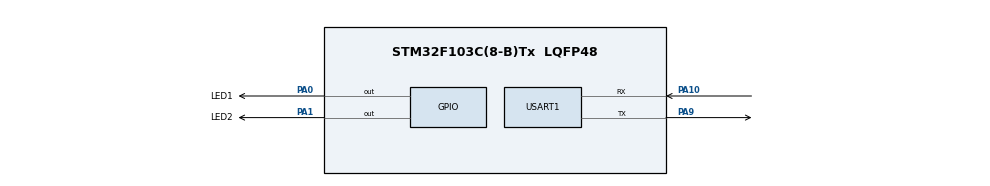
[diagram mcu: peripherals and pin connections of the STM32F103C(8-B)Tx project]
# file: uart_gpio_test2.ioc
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Mcu.Family=STM32F1
Mcu.Name=STM32F103C(8-B)Tx
Mcu.Package=LQFP48
NVIC.PriorityGroup=NVIC_PRIORITYGROUP_4
NVIC.USART1_IRQn=true\:0\:0\:false\:false\:true\:true\:true\:true
PA0-WKUP.GPIO_Label=LED1
PA0-WKUP.Signal=GPIO_Output
PA1.GPIO_Label=LED2
PA1.Signal=GPIO_Output
PA10.Mode=Asynchronous
PA10.Signal=USART1_RX
PA13.Mode=Serial_Wire
PA13.Signal=SYS_JTMS-SWDIO
PA14.Mode=Serial_Wire
PA14.Signal=SYS_JTCK-SWCLK
PA9.Mode=Asynchronous
PA9.Signal=USART1_TX
ProjectManager.HeapSize=0x200
ProjectManager.StackSize=0x400
ProjectManager.TargetToolchain=STM32CubeIDE
RCC.APB1Freq_Value=8000000
RCC.APB2Freq_Value=8000000
USART1.VirtualMode=VM_ASYNC
board=custom

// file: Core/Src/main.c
/* USER CODE BEGIN Header */
/**
  ******************************************************************************
  * @file           : main.c
  * @brief          : Main program body
  ******************************************************************************
  * @attention
  *
  * Copyright (c) 2026 STMicroelectronics.
  * All rights reserved.
  *
  * This software is licensed under terms that can be found in the LICENSE file
  * in the root directory of this software component.
  * If no LICENSE file comes with this software, it is provided AS-IS.
  *
  ******************************************************************************
  */
/* USER CODE END Header */
#include "main.h"

UART_HandleTypeDef huart1;

/* USER CODE BEGIN PV */
uint8_t rx_buf[2];  // UART'tan gelen 2 karakteri saklayan tampon (buffer)
/* USER CODE END PV */

void SystemClock_Config(void);
static void MX_GPIO_Init(void);
static void MX_USART1_UART_Init(void);

int main(void)
{

  /* MCU Configuration--------------------------------------------------------*/

  /* Reset of all peripherals, Initializes the Flash interface and the Systick. */
  HAL_Init();

  /* Configure the system clock */
  SystemClock_Config();

  /* Initialize all configured peripherals */
  MX_GPIO_Init();
  MX_USART1_UART_Init();
  /* USER CODE BEGIN 2 */
  HAL_UART_Receive_IT(&huart1, rx_buf, 2);  // UART'ı kesme modunda dinlemeye başlat: 2 karakter gelince kesme tetiklenir
  /* USER CODE END 2 */

  /* Infinite loop */
  while (1)
  {

  }
}

void SystemClock_Config(void)
{
  RCC_OscInitTypeDef RCC_OscInitStruct = {0};
  RCC_ClkInitTypeDef RCC_ClkInitStruct = {0};

  /** Initializes the RCC Oscillators according to the specified parameters
  * in the RCC_OscInitTypeDef structure.
  */
  RCC_OscInitStruct.OscillatorType = RCC_OSCILLATORTYPE_HSI;
  RCC_OscInitStruct.HSIState = RCC_HSI_ON;
  RCC_OscInitStruct.HSICalibrationValue = RCC_HSICALIBRATION_DEFAULT;
  RCC_OscInitStruct.PLL.PLLState = RCC_PLL_NONE;
  if (HAL_RCC_OscConfig(&RCC_OscInitStruct) != HAL_OK)
  {
    Error_Handler();
  }

  /** Initializes the CPU, AHB and APB buses clocks
  */
  RCC_ClkInitStruct.ClockType = RCC_CLOCKTYPE_HCLK|RCC_CLOCKTYPE_SYSCLK
                              |RCC_CLOCKTYPE_PCLK1|RCC_CLOCKTYPE_PCLK2;
  RCC_ClkInitStruct.SYSCLKSource = RCC_SYSCLKSOURCE_HSI;
  RCC_ClkInitStruct.AHBCLKDivider = RCC_SYSCLK_DIV1;
  RCC_ClkInitStruct.APB1CLKDivider = RCC_HCLK_DIV1;
  RCC_ClkInitStruct.APB2CLKDivider = RCC_HCLK_DIV1;

  if (HAL_RCC_ClockConfig(&RCC_ClkInitStruct, FLASH_LATENCY_0) != HAL_OK)
  {
    Error_Handler();
  }
}

static void MX_USART1_UART_Init(void)
{

  huart1.Instance = USART1;
  huart1.Init.BaudRate = 115200;
  huart1.Init.WordLength = UART_WORDLENGTH_8B;
  huart1.Init.StopBits = UART_STOPBITS_1;
  huart1.Init.Parity = UART_PARITY_NONE;
  huart1.Init.Mode = UART_MODE_TX_RX;
  huart1.Init.HwFlowCtl = UART_HWCONTROL_NONE;
  huart1.Init.OverSampling = UART_OVERSAMPLING_16;
  if (HAL_UART_Init(&huart1) != HAL_OK)
  {
    Error_Handler();
  }

}

static void MX_GPIO_Init(void)
{
  GPIO_InitTypeDef GPIO_InitStruct = {0};

  /* GPIO Ports Clock Enable */
  __HAL_RCC_GPIOA_CLK_ENABLE();

  /*Configure GPIO pin Output Level */
  HAL_GPIO_WritePin(GPIOA, LED1_Pin|LED2_Pin, GPIO_PIN_RESET);

  /*Configure GPIO pins : LED1_Pin LED2_Pin */
  GPIO_InitStruct.Pin = LED1_Pin|LED2_Pin;
  GPIO_InitStruct.Mode = GPIO_MODE_OUTPUT_PP;
  GPIO_InitStruct.Pull = GPIO_NOPULL;
  GPIO_InitStruct.Speed = GPIO_SPEED_FREQ_LOW;
  HAL_GPIO_Init(GPIOA, &GPIO_InitStruct);

}

/* USER CODE BEGIN 4 */

// Gelen karaktere göre verilen pini LOW, HIGH veya TOGGLE yapan fonksiyon
void apply_command(char c, GPIO_TypeDef *port, uint16_t pin)  // c: komut karakteri, port ve pin: kontrol edilecek pin
{                                                             // Fonksiyonun başlangıcı
  if (c == '0')                                               // Karakter '0' ise
    HAL_GPIO_WritePin(port, pin, GPIO_PIN_RESET);             // Pini LOW yap
  else if (c == '1')                                          // Karakter '1' ise
    HAL_GPIO_WritePin(port, pin, GPIO_PIN_SET);               // Pini HIGH yap
  else if (c == '2')                                          // Karakter '2' ise
    HAL_GPIO_TogglePin(port, pin);                            // Pinin durumunu tersine çevir (TOGGLE)
  // Başka bir karakter gelirse hiçbir şey yapılmaz (yok sayılır)
}                                                             // Fonksiyonun sonu

// 2 karakter alındığında HAL tarafından otomatik çağrılan kesme fonksiyonu
void HAL_UART_RxCpltCallback(UART_HandleTypeDef *huart)       // huart: veriyi alan UART
{                                                             // Fonksiyonun başlangıcı
  if (huart->Instance == USART1)                              // Veri USART1'den geldiyse
  {                                                           // if bloğunun başlangıcı
    apply_command(rx_buf[0], LED1_GPIO_Port, LED1_Pin);       // İlk karakter 1. pini (PA0) kontrol eder
    apply_command(rx_buf[1], LED2_GPIO_Port, LED2_Pin);       // İkinci karakter 2. pini (PA1) kontrol eder
    HAL_UART_Receive_IT(&huart1, rx_buf, 2);                  // Sonraki mesaj için alıcıyı tekrar kur
  }                                                           // if bloğunun sonu
}                                                             // Fonksiyonun sonu

/* USER CODE END 4 */

void Error_Handler(void)
{
  __disable_irq();
  while (1)
  {
  }
}
